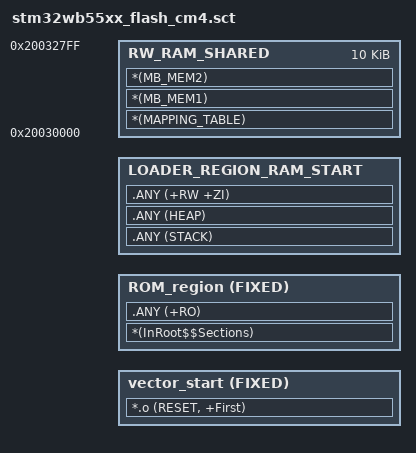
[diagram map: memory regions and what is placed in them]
#! armclang --target=arm-arm-none-eabi  -mcpu=cortex-m4 -E -xc
; *************************************************************
; *** Scatter-Loading Description File generated by uVision ***
; *************************************************************
#include "..\..\Linker_Common\MDK-ARM\mapping_sbsfu.h"
#include "..\..\Linker_Common\MDK-ARM\mapping_fwimg.h"


LR_ROM (LOADER_REGION_ROM_START) {
  vector_start (LOADER_REGION_ROM_START) FIXED VECTOR_SIZE {
  *.o (RESET, +First)
  }
  
  ROM_region (LOADER_REGION_ROM_START + VECTOR_SIZE) FIXED (LOADER_ROM_REGION_SIZE - VECTOR_SIZE){
  *(InRoot$$Sections)
  .ANY (+RO)
  }
  
  LOADER_REGION_RAM_START (LOADER_REGION_RAM_START) {
  .ANY (STACK)
  .ANY (HEAP)
  .ANY (+RW +ZI)
  }

  RW_RAM_SHARED 0x20030000 0x2800  {  ; RW data
   *(MAPPING_TABLE)
   *(MB_MEM1)
   *(MB_MEM2)
  }
}
